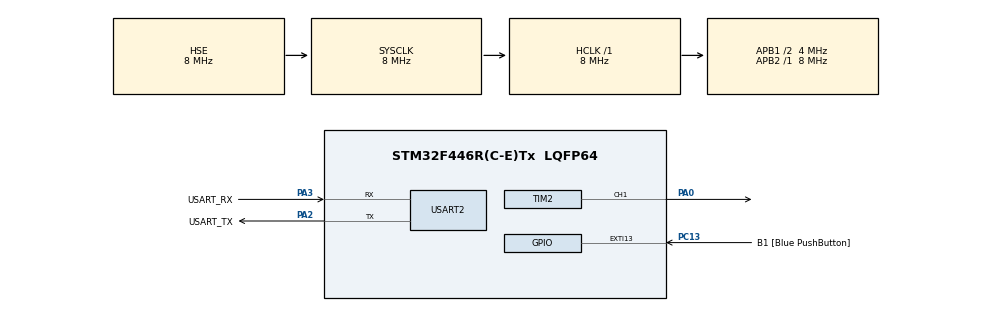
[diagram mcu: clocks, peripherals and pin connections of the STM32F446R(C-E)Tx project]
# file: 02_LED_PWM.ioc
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Dma.Request0=TIM2_CH1
Dma.TIM2_CH1.0.Direction=DMA_MEMORY_TO_PERIPH
Dma.TIM2_CH1.0.FIFOMode=DMA_FIFOMODE_DISABLE
Dma.TIM2_CH1.0.Instance=DMA1_Stream5
Dma.TIM2_CH1.0.MemDataAlignment=DMA_MDATAALIGN_WORD
Dma.TIM2_CH1.0.MemInc=DMA_MINC_ENABLE
Dma.TIM2_CH1.0.Mode=DMA_CIRCULAR
Dma.TIM2_CH1.0.PeriphDataAlignment=DMA_PDATAALIGN_WORD
Dma.TIM2_CH1.0.PeriphInc=DMA_PINC_DISABLE
Dma.TIM2_CH1.0.Priority=DMA_PRIORITY_LOW
Mcu.Family=STM32F4
Mcu.Name=STM32F446R(C-E)Tx
Mcu.Package=LQFP64
NVIC.DMA1_Stream5_IRQn=true\:0\:0\:false\:false\:true\:false\:true\:true
NVIC.PriorityGroup=NVIC_PRIORITYGROUP_0
PA0-WKUP.Signal=S_TIM2_CH1_ETR
PA13.GPIO_Label=TMS
PA13.Mode=Serial_Wire
PA13.Signal=SYS_JTMS-SWDIO
PA14.GPIO_Label=TCK
PA14.Mode=Serial_Wire
PA14.Signal=SYS_JTCK-SWCLK
PA2.GPIO_Label=USART_TX
PA2.Mode=Asynchronous
PA2.Signal=USART2_TX
PA3.GPIO_Label=USART_RX
PA3.Mode=Asynchronous
PA3.Signal=USART2_RX
PB3.GPIO_Label=SWO
PB3.Signal=SYS_JTDO-SWO
PC13.GPIO_Label=B1 [Blue PushButton]
PC13.GPIO_ModeDefaultEXTI=GPIO_MODE_IT_FALLING
PC13.Signal=GPXTI13
PC14-OSC32_IN.Mode=LSE-External-Oscillator
PC14-OSC32_IN.Signal=RCC_OSC32_IN
PC15-OSC32_OUT.Mode=LSE-External-Oscillator
PC15-OSC32_OUT.Signal=RCC_OSC32_OUT
PH0-OSC_IN.Mode=HSE-External-Oscillator
PH0-OSC_IN.Signal=RCC_OSC_IN
PH1-OSC_OUT.Mode=HSE-External-Oscillator
PH1-OSC_OUT.Signal=RCC_OSC_OUT
ProjectManager.HeapSize=0x200
ProjectManager.StackSize=0x400
ProjectManager.TargetToolchain=STM32CubeIDE
RCC.48MHZClocksFreq_Value=84000000
RCC.AHBFreq_Value=8000000
RCC.APB1CLKDivider=RCC_HCLK_DIV2
RCC.APB1Freq_Value=4000000
RCC.APB1TimFreq_Value=8000000
RCC.APB2Freq_Value=8000000
RCC.APB2TimFreq_Value=8000000
RCC.CortexFreq_Value=8000000
RCC.FLatency-AdvancedSettings=FLASH_LATENCY_0
RCC.HCLKFreq_Value=8000000
RCC.HSE_VALUE=8000000
RCC.HSI_VALUE=16000000
RCC.PLLN=336
RCC.PLLP=RCC_PLLP_DIV4
RCC.PLLSourceVirtual=RCC_PLLSOURCE_HSE
RCC.SYSCLKFreq_VALUE=8000000
RCC.SYSCLKSource=RCC_SYSCLKSOURCE_HSE
RCC.USBFreq_Value=84000000
RCC.VCOOutputFreq_Value=168000000
SH.S_TIM2_CH1_ETR.0=TIM2_CH1,PWM Generation1 CH1
TIM2.Channel-PWM\ Generation1\ CH1=TIM_CHANNEL_1
TIM2.Period=100-1
TIM2.Prescaler=8-1
USART2.VirtualMode=VM_ASYNC
VP_TIM2_VS_ClockSourceINT.Mode=Internal
board=NUCLEO-F446RE

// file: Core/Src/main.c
/* USER CODE BEGIN Header */
/**
 ******************************************************************************
 * @file           : main.c
 * @brief          : Main program body
 ******************************************************************************
 * @attention
 *
 * Copyright (c) 2026 STMicroelectronics.
 * All rights reserved.
 *
 * This software is licensed under terms that can be found in the LICENSE file
 * in the root directory of this software component.
 * If no LICENSE file comes with this software, it is provided AS-IS.
 *
 * ----- Private comments -------
 * The General Purpose and Advanced Timers are used to configure and generate PWM signals.
 *
 ******************************************************************************

 */
/* USER CODE END Header */
#include "main.h"

TIM_HandleTypeDef htim2;
DMA_HandleTypeDef hdma_tim2_ch1;

UART_HandleTypeDef huart2;

/* USER CODE BEGIN PV */
uint16_t pwm_data[105];
/* USER CODE END PV */

void SystemClock_Config(void);
static void MX_GPIO_Init(void);
static void MX_DMA_Init(void);
static void MX_TIM2_Init(void);
static void MX_USART2_UART_Init(void);

int main(void) {

	/* MCU Configuration--------------------------------------------------------*/

	/* Reset of all peripherals, Initializes the Flash interface and the Systick. */
	HAL_Init();

	/* Configure the system clock */
	SystemClock_Config();

	/* Initialize all configured peripherals */
	MX_GPIO_Init();
	MX_DMA_Init();
	MX_TIM2_Init();
	MX_USART2_UART_Init();
	/* USER CODE BEGIN 2 */
	//HAL_TIM_PWM_Start(&htim2, TIM_CHANNEL_1);
	/* USER CODE END 2 */

	/* Infinite loop */
	/* USER CODE BEGIN WHILE */
	/*
	// In the for loop method we manually increased the duty cycle by incrementing the value in Capture Compare Register
	// However this is not a good approach and DMA can be used to set the values in Capture Compare Registers
	// to increment or decrement the duty cycle
	//
	// Set the values to be loaded into CCR via DMA in an array
	for (int i = 0; i < 100; i++)
		pwm_data[i] = i;
	pwm_data[100] = 0;
	pwm_data[101] = 0;
	pwm_data[102] = 0;
	pwm_data[103] = 0;
	pwm_data[104] = 0;

	HAL_TIM_PWM_Start_DMA(&htim2, TIM_CHANNEL_1, (uint32_t*) pwm_data, 105);*/

	while (1) {

		 //
		 // We want to gradually increase the duty cycle from 1 % to 100 %
		 //
		 for (int duty = 0; duty <= 99; duty += 1) {
		 // Set the compare register of TIM2 Channel 1 to value of 'duty' (to increment the PWM duty cycle)
		 __HAL_TIM_SET_COMPARE(&htim2, TIM_CHANNEL_1, duty);
		 HAL_Delay(50);		// Wait 50 ms before changing the duty cycle
		 }

		/* USER CODE END WHILE */

	}
}

void SystemClock_Config(void) {
	RCC_OscInitTypeDef RCC_OscInitStruct = { 0 };
	RCC_ClkInitTypeDef RCC_ClkInitStruct = { 0 };

	/** Configure the main internal regulator output voltage
	 */
	__HAL_RCC_PWR_CLK_ENABLE();
	__HAL_PWR_VOLTAGESCALING_CONFIG(PWR_REGULATOR_VOLTAGE_SCALE3);

	/** Initializes the RCC Oscillators according to the specified parameters
	 * in the RCC_OscInitTypeDef structure.
	 */
	RCC_OscInitStruct.OscillatorType = RCC_OSCILLATORTYPE_HSE;
	RCC_OscInitStruct.HSEState = RCC_HSE_ON;
	RCC_OscInitStruct.PLL.PLLState = RCC_PLL_NONE;
	if (HAL_RCC_OscConfig(&RCC_OscInitStruct) != HAL_OK) {
		Error_Handler();
	}

	/** Initializes the CPU, AHB and APB buses clocks
	 */
	RCC_ClkInitStruct.ClockType = RCC_CLOCKTYPE_HCLK | RCC_CLOCKTYPE_SYSCLK
			| RCC_CLOCKTYPE_PCLK1 | RCC_CLOCKTYPE_PCLK2;
	RCC_ClkInitStruct.SYSCLKSource = RCC_SYSCLKSOURCE_HSE;
	RCC_ClkInitStruct.AHBCLKDivider = RCC_SYSCLK_DIV1;
	RCC_ClkInitStruct.APB1CLKDivider = RCC_HCLK_DIV2;
	RCC_ClkInitStruct.APB2CLKDivider = RCC_HCLK_DIV1;

	if (HAL_RCC_ClockConfig(&RCC_ClkInitStruct, FLASH_LATENCY_0) != HAL_OK) {
		Error_Handler();
	}
}

static void MX_TIM2_Init(void) {

	TIM_ClockConfigTypeDef sClockSourceConfig = { 0 };
	TIM_MasterConfigTypeDef sMasterConfig = { 0 };
	TIM_OC_InitTypeDef sConfigOC = { 0 };

	htim2.Instance = TIM2;
	htim2.Init.Prescaler = 8 - 1;
	htim2.Init.CounterMode = TIM_COUNTERMODE_UP;
	htim2.Init.Period = 100 - 1;
	htim2.Init.ClockDivision = TIM_CLOCKDIVISION_DIV1;
	htim2.Init.AutoReloadPreload = TIM_AUTORELOAD_PRELOAD_DISABLE;
	if (HAL_TIM_Base_Init(&htim2) != HAL_OK) {
		Error_Handler();
	}
	sClockSourceConfig.ClockSource = TIM_CLOCKSOURCE_INTERNAL;
	if (HAL_TIM_ConfigClockSource(&htim2, &sClockSourceConfig) != HAL_OK) {
		Error_Handler();
	}
	if (HAL_TIM_PWM_Init(&htim2) != HAL_OK) {
		Error_Handler();
	}
	sMasterConfig.MasterOutputTrigger = TIM_TRGO_RESET;
	sMasterConfig.MasterSlaveMode = TIM_MASTERSLAVEMODE_DISABLE;
	if (HAL_TIMEx_MasterConfigSynchronization(&htim2, &sMasterConfig)
			!= HAL_OK) {
		Error_Handler();
	}
	sConfigOC.OCMode = TIM_OCMODE_PWM1;
	sConfigOC.Pulse = 0;
	sConfigOC.OCPolarity = TIM_OCPOLARITY_HIGH;
	sConfigOC.OCFastMode = TIM_OCFAST_DISABLE;
	if (HAL_TIM_PWM_ConfigChannel(&htim2, &sConfigOC, TIM_CHANNEL_1)
			!= HAL_OK) {
		Error_Handler();
	}
	HAL_TIM_MspPostInit(&htim2);

}

static void MX_USART2_UART_Init(void) {

	huart2.Instance = USART2;
	huart2.Init.BaudRate = 115200;
	huart2.Init.WordLength = UART_WORDLENGTH_8B;
	huart2.Init.StopBits = UART_STOPBITS_1;
	huart2.Init.Parity = UART_PARITY_NONE;
	huart2.Init.Mode = UART_MODE_TX_RX;
	huart2.Init.HwFlowCtl = UART_HWCONTROL_NONE;
	huart2.Init.OverSampling = UART_OVERSAMPLING_16;
	if (HAL_UART_Init(&huart2) != HAL_OK) {
		Error_Handler();
	}

}

static void MX_DMA_Init(void) {

	/* DMA controller clock enable */
	__HAL_RCC_DMA1_CLK_ENABLE();

	/* DMA interrupt init */
	/* DMA1_Stream5_IRQn interrupt configuration */
	HAL_NVIC_SetPriority(DMA1_Stream5_IRQn, 0, 0);
	HAL_NVIC_EnableIRQ(DMA1_Stream5_IRQn);

}

static void MX_GPIO_Init(void) {
	GPIO_InitTypeDef GPIO_InitStruct = { 0 };

	/* GPIO Ports Clock Enable */
	__HAL_RCC_GPIOC_CLK_ENABLE();
	__HAL_RCC_GPIOH_CLK_ENABLE();
	__HAL_RCC_GPIOA_CLK_ENABLE();
	__HAL_RCC_GPIOB_CLK_ENABLE();

	/*Configure GPIO pin : B1_Pin */
	GPIO_InitStruct.Pin = B1_Pin;
	GPIO_InitStruct.Mode = GPIO_MODE_IT_FALLING;
	GPIO_InitStruct.Pull = GPIO_NOPULL;
	HAL_GPIO_Init(B1_GPIO_Port, &GPIO_InitStruct);

}

void Error_Handler(void) {
	__disable_irq();
	while (1) {
	}
}
